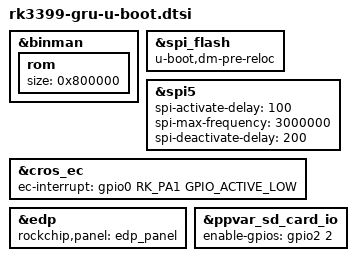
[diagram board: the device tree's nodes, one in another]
// SPDX-License-Identifier: GPL-2.0+
/*
 * Copyright (C) 2019 Jagan Teki <jagan@amarulasolutions.com>
 */

#include "rk3399-u-boot.dtsi"

&binman {
	rom {
		size = <0x800000>;
	};
};

&spi_flash {
	u-boot,dm-pre-reloc;
};

&spi5 {
	spi-activate-delay = <100>;
	spi-max-frequency = <3000000>;
	spi-deactivate-delay = <200>;
};

&cros_ec {
	ec-interrupt = <&gpio0 RK_PA1 GPIO_ACTIVE_LOW>;
};

&edp {
	rockchip,panel = <&edp_panel>;
};

&ppvar_sd_card_io {
	enable-gpios = <&gpio2 2 GPIO_ACTIVE_HIGH>;
};
